# lpc1759 register map
File version: 0.2
LPC176x/LPC175x M3
CPU: CM3 r0p0, little endian, MPU, no FPU, 5 interrupt priority bits
Registers are 32-bit, read-write, reset 0x0 unless marked. A register's access mark holds for its fields unless they carry their own. Offsets are from the block's base; lines under a group give offsets from that group; [hi:lo] are bit positions; {n}, {i} and the like mark numbered series; 'fields as' and 'values as' point back to an identical list; <NAME> marks a mode.

## Memory map
0x2009C000 GPIO0 size 0x20 — General Purpose I/O
0x2009C020 GPIO1 size 0x20
0x2009C040 GPIO2 size 0x20
0x2009C060 GPIO3 size 0x20
0x2009C080 GPIO4 size 0x20
0x40000000 WDT size 0xFFF — Watchdog Timer (WDT)
0x40004000 TIMER0 size 0xFFF — Timer0/1/2/3
0x40008000 TIMER1 size 0xFFF
0x4000C000 UART0 size 0xFFF — UART0/2/3
0x40010000 UART1 size 0xFFF
0x40018000 PWM1 size 0xFFF — Pulse Width Modulators (PWM1)
0x4001C000 I2C0 size 0xFFF — I2C bus interface
0x40020000 SPI size 0xFFF
0x40024000 RTC size 0xFFF — Real Time Clock (RTC)
0x40028080 GPIOINT size 0xFFF — GPIO
0x4002C000 PINCONNECT size 0xFFF — Pin connect block
0x40030000 SSP1 size 0xFFF — SSP controller
0x40034000 ADC size 0xFFF — Analog-to-Digital Converter (ADC)
0x40038000 CANAFRAM size 0xFFF — CAN acceptance filter RAM
0x4003C000 CANAF size 0xFFF — CAN controller acceptance filter
0x40040000 CCAN size 0xFFF — Central CAN controller
0x40044000 CAN1 size 0xFFF — CAN1 controller
0x40048000 CAN2 size 0xFFF
0x4005C000 I2C1 size 0xFFF
0x40088000 SSP0 size 0xFFF — SSP0 controller
0x4008C000 DAC size 0xFFF — Digital-to-Analog Converter (DAC)
0x40090000 TIMER2 size 0xFFF
0x40094000 TIMER3 size 0xFFF
0x40098000 UART2 size 0xFFF
0x4009C000 UART3 size 0xFFF
0x400A0000 I2C2 size 0xFFF
0x400A8000 I2S size 0xFFF — I2S interface
0x400B0000 RITIMER size 0xFFF — Repetitive Interrupt Timer (RIT)
0x400B8000 MCPWM size 0xFFF — Motor Control PWM
0x400BC000 QEI size 0xFFF — Quadrature Encoder Interface (QEI)
0x400FC000 SYSCON size 0xFFF — System and clock control
0x50000000 EMAC size 0xFFF — Ethernet
0x50004000 GPDMA size 0xFFF — General purpose DMA controller
0x5000C000 USB size 0xFFF — USB device/host/OTG controller

## Interrupts
0 WDT
1 TIMER0
2 TIMER1
3 TIMER2
4 TIMER3
5 UART0
6 UART1
7 UART2
8 UART3
9 PWM1
10 I2C0
11 I2C1
12 I2C2
13 SPI
14 SSP0
15 SSP1
16 PLL0 (SYSCON)
17 RTC
18 EINT0 (SYSCON)
19 EINT1 (SYSCON)
20 EINT2 (SYSCON)
21 EINT3 (SYSCON)
22 ADC
23 BOD (SYSCON)
24 USB
25 CAN (CAN1)
26 DMA (GPDMA)
27 I2S
28 ENET (EMAC)
29 RIT (RITIMER)
30 MCPWM
31 QEI
32 PLL1 (SYSCON)
33 USBActivity (USB)
34 CANActivity (CCAN)

## WDT — Watchdog Timer (WDT)
Base 0x40000000
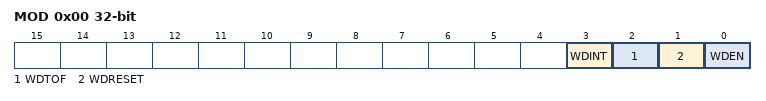
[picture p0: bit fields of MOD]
0x00 MOD — Watchdog mode register. This register determines the basic mode and status of the Watchdog Timer.
  [3] WDINT — Watchdog interrupt flag. Cleared by software.
  [2] WDTOF — Watchdog time-out flag. Set when the watchdog timer times out, cleared by software.
  [1] WDRESET — Watchdog reset enable bit. This bit is Set Only. See Table 652.
    0=NORESET (A watchdog timeout will not cause a chip reset.); 1=RESET (A watchdog timeout will cause a chip reset.)
  [0] WDEN — Watchdog enable bit. This bit is Set Only.
    0=STOP (The watchdog timer is stopped.); 1=RUN (The watchdog timer is running.)
0x04 TC reset 0xFF — Watchdog timer constant register. The value in this register determines the time-out value.
  [31:0] Count — Watchdog time-out interval.
0x08 FEED wo reset not defined — Watchdog feed sequence register. Writing 0xAA followed by 0x55 to this register reloads the Watchdog timer with the value contained in WDTC.
  [7:0] Feed — Feed value should be 0xAA followed by 0x55.
0x0C TV ro reset 0xFF — Watchdog timer value register. This register reads out the current value of the Watchdog timer.
  [31:0] Count — Counter timer value.
0x10 CLKSEL — Watchdog clock select register.
  [31] LOCK — If this bit is set to one writing to this register does not affect bit 0. The clock source can only be changed by first clearing this bit, then writing the new value of bit 0.
    0=UNLOCKED (This bit is set to 0 on any reset. It cannot be cleared by software.); 1=LOCKED (Software can set this bit to 1 at any time. Once WDLOCK is set, the bits of this register cannot be modified.)
  [30:1] RESERVED — Reserved, user software should not write ones to reserved bits. The value read from a reserved bit is not defined.
  [1:0] CLKSEL — Selects source of WDT clock
    0=IRC; 1=PCLK (Peripheral clock); 2=RTCOSC (RTC oscillator)
